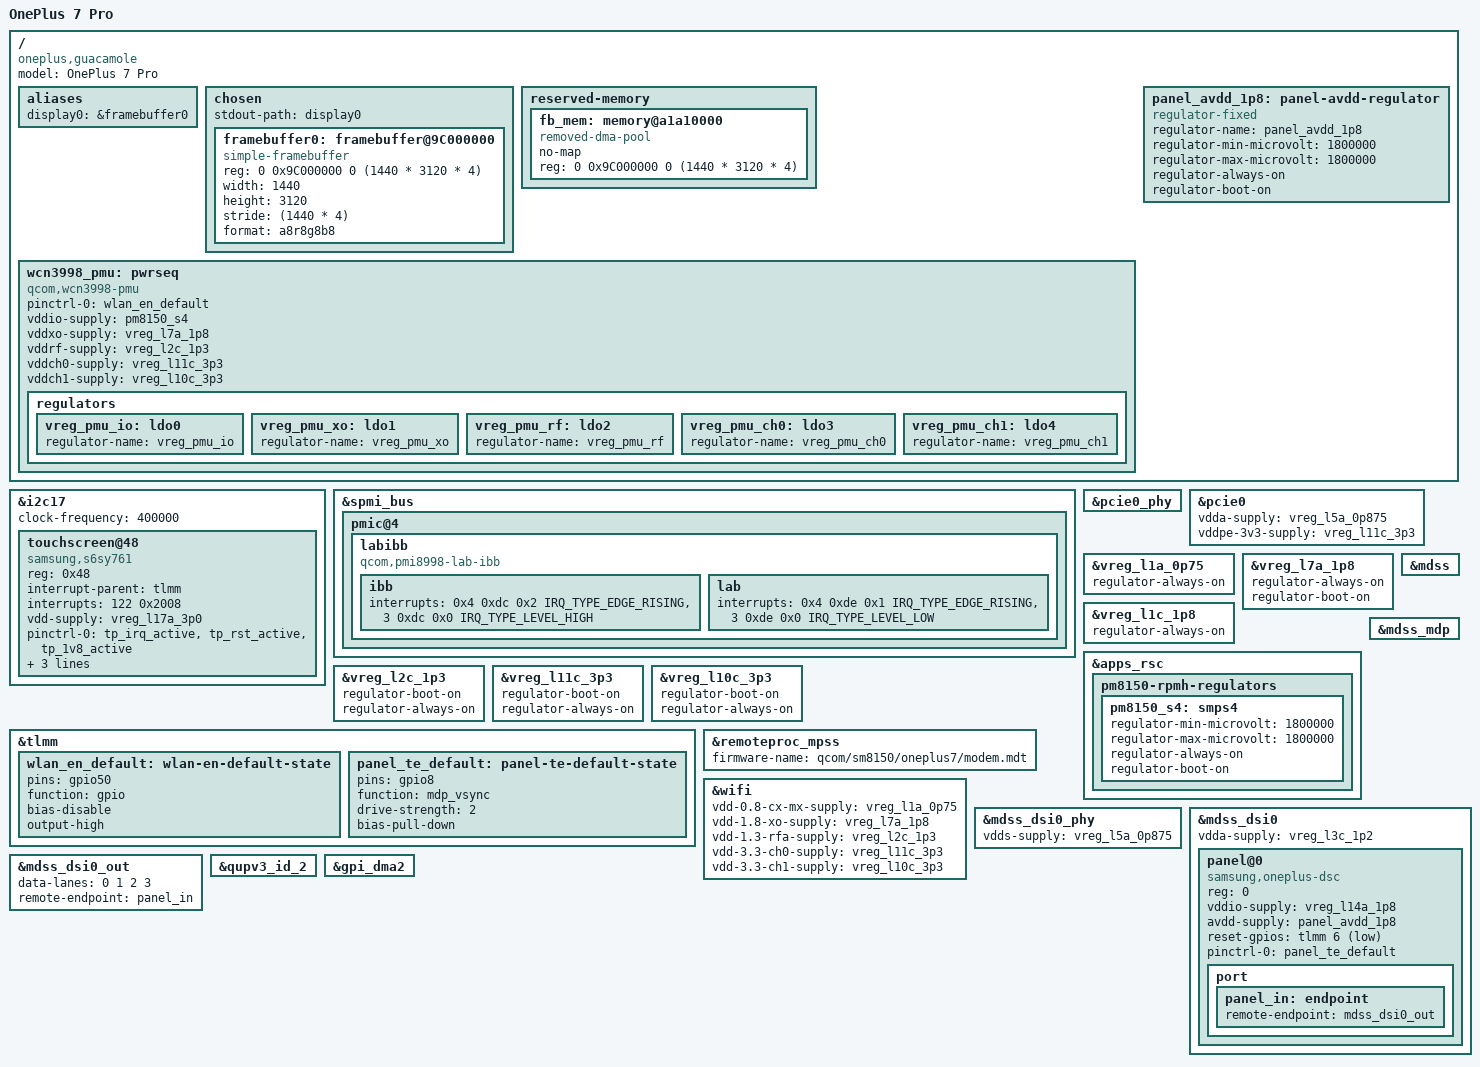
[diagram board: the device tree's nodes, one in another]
// SPDX-License-Identifier: BSD-3-Clause
/*
 * Devicetree for the OnePlus 7 Pro. This device uses a samsung touch driver
 * and has a 1440p panel but is otherwise similar to the rest of the series.
 *
 * Copyright (c) 2021, Caleb Connolly <caleb@connolly.tech>
 */

/dts-v1/;

#include <dt-bindings/regulator/qcom,rpmh-regulator.h>
#include <dt-bindings/gpio/gpio.h>
#include "sm8150-oneplus-common.dtsi"

/ {
	model = "OnePlus 7 Pro";
	compatible = "oneplus,guacamole", "oneplus,oneplus7", "qcom,sm8150";

	aliases {
		display0 = &framebuffer0;
	};

	chosen {
		#address-cells = <2>;
		#size-cells = <2>;
		ranges;
		stdout-path = "display0";

		/*
		 * hack: Use framebuffer setup by the bootloader for simplefb.
		 * the address is taken from the bootloader config (strings xbl.img | grep "Display Reserved")
		 */
		framebuffer0: framebuffer@9C000000 {
			compatible = "simple-framebuffer";
			reg = <0 0x9C000000 0 (1440 * 3120 * 4)>;
			width = <1440>;
			height = <3120>;
			stride = <(1440 * 4)>;
			format = "a8r8g8b8";
			status = "okay";

		};
	};

	reserved-memory {
	// hack: Bootloader framebuffer memory region
		fb_mem: memory@a1a10000 {
			compatible = "removed-dma-pool";
			no-map;
			reg = <0 0x9C000000 0 (1440 * 3120 * 4)>;
		};
	};
};

&i2c17 {
	status = "okay";
	clock-frequency = <400000>;

	touchscreen@48 {
		compatible = "samsung,s6sy761";
		status = "okay";
		reg = <0x48>;
		interrupt-parent = <&tlmm>;
		interrupts = <122 0x2008>;
		vdd-supply = <&vreg_l17a_3p0>;

		pinctrl-names = "default";
		pinctrl-0 = <&tp_irq_active &tp_rst_active &tp_1v8_active>;

		touchscreen-size-x = <1440>;
		touchscreen-size-y = <3120>;
		touchscreen-inverted-y;
	};
};
/* ---- OnePlus 7 Pro display (LAB/IBB + panel) ---- */
&spmi_bus {
	pmic@4 {
	labibb {
		compatible = "qcom,pmi8998-lab-ibb";

		ibb: ibb {
			interrupts = <0x4 0xdc 0x2 IRQ_TYPE_EDGE_RISING>,
				     <3 0xdc 0x0 IRQ_TYPE_LEVEL_HIGH>;
			interrupt-names = "sc-err", "ocp";
		};

		lab: lab {
			interrupts = <0x4 0xde 0x1 IRQ_TYPE_EDGE_RISING>,
				     <3 0xde 0x0 IRQ_TYPE_LEVEL_LOW>;
			interrupt-names = "sc-err", "ocp";
		};
	};
	};
};

/* ---- 第一阶段：只打开 PCIe 控制器，验证总线能否枚举 ---- */

/* ---- 显示暂时关掉（panel 链路未完成，开了会崩）---- */
/* ---- WCN3998 供电（按 vendor icnss 映射）：真实 regulator，不是 dummy ---- */

/* 驱动实际使用的 supply 名（dmesg 报的） */

/* ---- WCN3998 电源序列（pwrseq）：vddio 单独，其余 4 路 ---- */



/* ---- PCIe0：主线节点已含 perst/wake/phys/pd，只需 enable 控制器和 PHY ---- */

&pcie0_phy {
	status = "okay";
};

/* PCIe0：主线节点已含 perst/wake/phys/power-domains，这里只补供电并 enable */
&pcie0 {
	status = "okay";
	vdda-supply = <&vreg_l5a_0p875>;      /* 0.875V PCIe 模拟 */
	vddpe-3v3-supply = <&vreg_l11c_3p3>;  /* 3.3V 给下游设备/WiFi */
};

/* WiFi 芯片常电（SoC CX/IO 需在 probe 前上电，否则 ROM 不运行、无 FW_READY） */
&vreg_l1a_0p75 {
	regulator-always-on;
};

&vreg_l7a_1p8 {
	regulator-always-on;
};

&vreg_l1c_1p8 {
	regulator-always-on;
};
/* always-on-wifi */


/* ---- WCN3998 PMU（按 sm8150-hdk 的写法：pwrseq + 内部 fixed LDO） ---- */
/ {
	wcn3998_pmu: pwrseq {
		compatible = "qcom,wcn3998-pmu";

		pinctrl-0 = <&wlan_en_default>;
		pinctrl-names = "default";

		vddio-supply  = <&pm8150_s4>;
		vddxo-supply  = <&vreg_l7a_1p8>;
		vddrf-supply  = <&vreg_l2c_1p3>;
		vddch0-supply = <&vreg_l11c_3p3>;
		vddch1-supply = <&vreg_l10c_3p3>;


		regulators {
			vreg_pmu_io: ldo0 {
				regulator-name = "vreg_pmu_io";
			};

			vreg_pmu_xo: ldo1 {
				regulator-name = "vreg_pmu_xo";
			};

			vreg_pmu_rf: ldo2 {
				regulator-name = "vreg_pmu_rf";
			};

			vreg_pmu_ch0: ldo3 {
				regulator-name = "vreg_pmu_ch0";
			};

			vreg_pmu_ch1: ldo4 {
				regulator-name = "vreg_pmu_ch1";
			};
		};
	};
};



/* PM8150 S4A 1.8V —— WCN3998 的 VDDIO（HDK 用 s4a_1p8，必须 boot-on） */
&apps_rsc {
	pm8150-rpmh-regulators {
		pm8150_s4: smps4 {
			regulator-min-microvolt = <1800000>;
			regulator-max-microvolt = <1800000>;
			regulator-always-on;
			regulator-boot-on;
		};
	};
};

&vreg_l7a_1p8 {
	regulator-boot-on;
};

&vreg_l2c_1p3 {
	regulator-boot-on;
	regulator-always-on;
};

&vreg_l11c_3p3 {
	regulator-boot-on;
	regulator-always-on;
};

&vreg_l10c_3p3 {
	regulator-boot-on;
	regulator-always-on;
};

&tlmm {
	wlan_en_default: wlan-en-default-state {
		pins = "gpio50";
		function = "gpio";
		bias-disable;
		output-high;
	};
};

/* Nura 写法：只 status okay，用 dummy regulator，不接管供电/pwrseq */

&remoteproc_mpss {
	status = "okay";
	firmware-name = "qcom/sm8150/oneplus7/modem.mdt";
};

&wifi {
	status = "okay";

	vdd-0.8-cx-mx-supply = <&vreg_l1a_0p75>;
	vdd-1.8-xo-supply = <&vreg_l7a_1p8>;
	vdd-1.3-rfa-supply = <&vreg_l2c_1p3>;
	vdd-3.3-ch0-supply = <&vreg_l11c_3p3>;
	vdd-3.3-ch1-supply = <&vreg_l10c_3p3>;
};

/* ---------- 原生 DSI + Samsung OnePlus DSC 面板 ---------- */

/ {
	panel_avdd_1p8: panel-avdd-regulator {
		compatible = "regulator-fixed";
		regulator-name = "panel_avdd_1p8";
		regulator-min-microvolt = <1800000>;
		regulator-max-microvolt = <1800000>;
		regulator-always-on;
		regulator-boot-on;
	};
};

&tlmm {
	panel_te_default: panel-te-default-state {
		pins = "gpio8";
		function = "mdp_vsync";
		drive-strength = <2>;
		bias-pull-down;
	};
};

/* ================= 显示（原生 DSI + OnePlus DSC 面板） ================= */

&mdss {
	status = "okay";
};

&mdss_mdp {
	status = "okay";
};

&mdss_dsi0_phy {
	status = "okay";
	vdds-supply = <&vreg_l5a_0p875>;
};

&mdss_dsi0 {
	status = "okay";
	vdda-supply = <&vreg_l3c_1p2>;

	panel@0 {
		compatible = "samsung,oneplus-dsc";
		reg = <0>;

		vddio-supply = <&vreg_l14a_1p8>;
		avdd-supply = <&panel_avdd_1p8>;

		reset-gpios = <&tlmm 6 GPIO_ACTIVE_LOW>;
		pinctrl-0 = <&panel_te_default>;
		pinctrl-names = "default";

		port {
			panel_in: endpoint {
				remote-endpoint = <&mdss_dsi0_out>;
			};
		};
	};
};

&mdss_dsi0_out {
	data-lanes = <0 1 2 3>;
	remote-endpoint = <&panel_in>;
	status = "okay";
};

/* 触摸 (S6SY761 @ i2c17) 所在的 QUP wrapper */
&qupv3_id_2 {
	status = "okay";
};

&gpi_dma2 {
	status = "okay";
};
